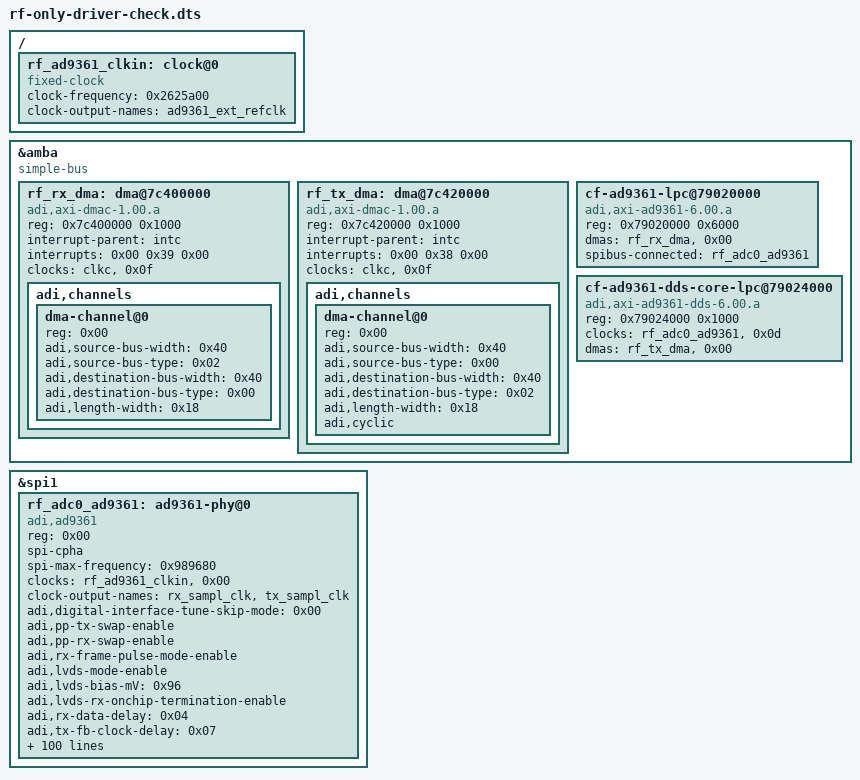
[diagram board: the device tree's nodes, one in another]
/dts-v1/;
/plugin/;
/ {
fragment@0 {
		target-path = "/";

		__overlay__ {


			rf_ad9361_clkin: clock@0 {
				compatible = "fixed-clock";
				clock-frequency = <0x2625a00>;
				clock-output-names = "ad9361_ext_refclk";
				#clock-cells = <0x00>;


			};
		};
	};

	fragment@1 {
		target = <&amba>;

		__overlay__ {
			compatible = "simple-bus";
			#address-cells = <0x01>;
			#size-cells = <0x01>;
			ranges;


			rf_rx_dma: dma@7c400000 {
				compatible = "adi,axi-dmac-1.00.a";
				reg = <0x7c400000 0x1000>;
				#dma-cells = <0x01>;
				interrupt-parent = <&intc>;
				interrupts = <0x00 0x39 0x00>;
				clocks = <&clkc>, <0x0f>;


				adi,channels {
					#size-cells = <0x00>;
					#address-cells = <0x01>;

					dma-channel@0 {
						reg = <0x00>;
						adi,source-bus-width = <0x40>;
						adi,source-bus-type = <0x02>;
						adi,destination-bus-width = <0x40>;
						adi,destination-bus-type = <0x00>;
						adi,length-width = <0x18>;
					};
				};
			};

			rf_tx_dma: dma@7c420000 {
				compatible = "adi,axi-dmac-1.00.a";
				reg = <0x7c420000 0x1000>;
				#dma-cells = <0x01>;
				interrupt-parent = <&intc>;
				interrupts = <0x00 0x38 0x00>;
				clocks = <&clkc>, <0x0f>;


				adi,channels {
					#size-cells = <0x00>;
					#address-cells = <0x01>;

					dma-channel@0 {
						reg = <0x00>;
						adi,source-bus-width = <0x40>;
						adi,source-bus-type = <0x00>;
						adi,destination-bus-width = <0x40>;
						adi,destination-bus-type = <0x02>;
						adi,length-width = <0x18>;
						adi,cyclic;
					};
				};
			};

			cf-ad9361-lpc@79020000 {
				compatible = "adi,axi-ad9361-6.00.a";
				reg = <0x79020000 0x6000>;
				dmas = <&rf_rx_dma>, <0x00>;
				dma-names = "rx";
				spibus-connected = <&rf_adc0_ad9361>;


			};

			cf-ad9361-dds-core-lpc@79024000 {
				compatible = "adi,axi-ad9361-dds-6.00.a";
				reg = <0x79024000 0x1000>;
				clocks = <&rf_adc0_ad9361>, <0x0d>;
				clock-names = "sampl_clk";
				dmas = <&rf_tx_dma>, <0x00>;
				dma-names = "tx";


			};
		};
	};

	fragment@2 {
		target = <&spi1>;

		__overlay__ {
			status = "okay";


			rf_adc0_ad9361: ad9361-phy@0 {
				compatible = "adi,ad9361";
				reg = <0x00>;
				spi-cpha;
				spi-max-frequency = <0x989680>;
				clocks = <&rf_ad9361_clkin>, <0x00>;
				clock-names = "ad9361_ext_refclk";
				clock-output-names = "rx_sampl_clk", "tx_sampl_clk";
				#clock-cells = <0x01>;
				adi,digital-interface-tune-skip-mode = <0x00>;
				adi,pp-tx-swap-enable;
				adi,pp-rx-swap-enable;
				adi,rx-frame-pulse-mode-enable;
				adi,lvds-mode-enable;
				adi,lvds-bias-mV = <0x96>;
				adi,lvds-rx-onchip-termination-enable;
				adi,rx-data-delay = <0x04>;
				adi,tx-fb-clock-delay = <0x07>;
				adi,dcxo-coarse-and-fine-tune = <0x08 0x1720>;
				adi,2rx-2tx-mode-enable;
				adi,frequency-division-duplex-mode-enable;
				adi,rx-rf-port-input-select = <0x00>;
				adi,tx-rf-port-input-select = <0x00>;
				adi,tx-attenuation-mdB = <0x2710>;
				adi,tx-lo-powerdown-managed-enable;
				adi,rf-rx-bandwidth-hz = <0x112a880>;
				adi,rf-tx-bandwidth-hz = <0x112a880>;
				adi,rx-synthesizer-frequency-hz = <0x00 0x8f0d1800>;
				adi,tx-synthesizer-frequency-hz = <0x00 0x92080880>;
				adi,rx-path-clock-frequencies = <0x3a980000 0xea60000 0x7530000 0x3a98000 0x1d4c000 0x1d4c000>;
				adi,tx-path-clock-frequencies = <0x3a980000 0x7530000 0x7530000 0x3a98000 0x1d4c000 0x1d4c000>;
				adi,gc-rx1-mode = <0x02>;
				adi,gc-rx2-mode = <0x02>;
				adi,gc-adc-ovr-sample-size = <0x04>;
				adi,gc-adc-small-overload-thresh = <0x2f>;
				adi,gc-adc-large-overload-thresh = <0x3a>;
				adi,gc-lmt-overload-high-thresh = <0x320>;
				adi,gc-lmt-overload-low-thresh = <0x2c0>;
				adi,gc-dec-pow-measurement-duration = <0x2000>;
				adi,gc-low-power-thresh = <0x18>;
				adi,mgc-inc-gain-step = <0x02>;
				adi,mgc-dec-gain-step = <0x02>;
				adi,mgc-split-table-ctrl-inp-gain-mode = <0x00>;
				adi,agc-attack-delay-extra-margin-us = <0x01>;
				adi,agc-outer-thresh-high = <0x05>;
				adi,agc-outer-thresh-high-dec-steps = <0x02>;
				adi,agc-inner-thresh-high = <0x0a>;
				adi,agc-inner-thresh-high-dec-steps = <0x01>;
				adi,agc-inner-thresh-low = <0x0c>;
				adi,agc-inner-thresh-low-inc-steps = <0x01>;
				adi,agc-outer-thresh-low = <0x12>;
				adi,agc-outer-thresh-low-inc-steps = <0x02>;
				adi,agc-adc-small-overload-exceed-counter = <0x0a>;
				adi,agc-adc-large-overload-exceed-counter = <0x0a>;
				adi,agc-adc-large-overload-inc-steps = <0x02>;
				adi,agc-lmt-overload-large-exceed-counter = <0x0a>;
				adi,agc-lmt-overload-small-exceed-counter = <0x0a>;
				adi,agc-lmt-overload-large-inc-steps = <0x02>;
				adi,agc-gain-update-interval-us = <0x3e8>;
				adi,fagc-dec-pow-measurement-duration = <0x40>;
				adi,fagc-lp-thresh-increment-steps = <0x01>;
				adi,fagc-lp-thresh-increment-time = <0x05>;
				adi,fagc-energy-lost-stronger-sig-gain-lock-exit-cnt = <0x08>;
				adi,fagc-final-overrange-count = <0x03>;
				adi,fagc-gain-index-type-after-exit-rx-mode = <0x00>;
				adi,fagc-lmt-final-settling-steps = <0x01>;
				adi,fagc-lock-level = <0x0a>;
				adi,fagc-lock-level-gain-increase-upper-limit = <0x05>;
				adi,fagc-lock-level-lmt-gain-increase-enable;
				adi,fagc-lpf-final-settling-steps = <0x01>;
				adi,fagc-optimized-gain-offset = <0x05>;
				adi,fagc-power-measurement-duration-in-state5 = <0x40>;
				adi,fagc-rst-gla-engergy-lost-goto-optim-gain-enable;
				adi,fagc-rst-gla-engergy-lost-sig-thresh-below-ll = <0x0a>;
				adi,fagc-rst-gla-engergy-lost-sig-thresh-exceeded-enable;
				adi,fagc-rst-gla-if-en-agc-pulled-high-mode = <0x00>;
				adi,fagc-rst-gla-large-adc-overload-enable;
				adi,fagc-rst-gla-large-lmt-overload-enable;
				adi,fagc-rst-gla-stronger-sig-thresh-above-ll = <0x0a>;
				adi,fagc-rst-gla-stronger-sig-thresh-exceeded-enable;
				adi,fagc-state-wait-time-ns = <0x104>;
				adi,fagc-use-last-lock-level-for-set-gain-enable;
				adi,rssi-restart-mode = <0x03>;
				adi,rssi-delay = <0x01>;
				adi,rssi-wait = <0x01>;
				adi,rssi-duration = <0x3e8>;
				adi,ctrl-outs-index = <0x00>;
				adi,ctrl-outs-enable-mask = <0xff>;
				adi,temp-sense-measurement-interval-ms = <0x3e8>;
				adi,temp-sense-offset-signed = <0xce>;
				adi,temp-sense-periodic-measurement-enable;
				adi,aux-dac-manual-mode-enable;
				adi,aux-dac1-default-value-mV = <0x00>;
				adi,aux-dac1-rx-delay-us = <0x00>;
				adi,aux-dac1-tx-delay-us = <0x00>;
				adi,aux-dac2-default-value-mV = <0x00>;
				adi,aux-dac2-rx-delay-us = <0x00>;
				adi,aux-dac2-tx-delay-us = <0x00>;
				en_agc-gpios = <&gpio0>, <0x62 0x00>;
				sync-gpios = <&gpio0>, <0x63 0x00>;
				reset-gpios = <&gpio0>, <0x64 0x00>;
				enable-gpios = <&gpio0>, <0x65 0x00>;
				txnrx-gpios = <&gpio0>, <0x66 0x00>;


			};
		};
	};
};
